# R9A09G057H register map
Vendor: Renesas Electronics; File version: 1.0
Registers are 32-bit, read-write, no defined reset value unless marked. A register's access mark holds for its fields unless they carry their own. Offsets are from the block's base; [hi:lo] are bit positions; {n}, {i} and the like mark numbered series; 'fields as' and 'values as' point back to an identical list.

## R_CPG — IO define file for cpg.
Base 0x10420010
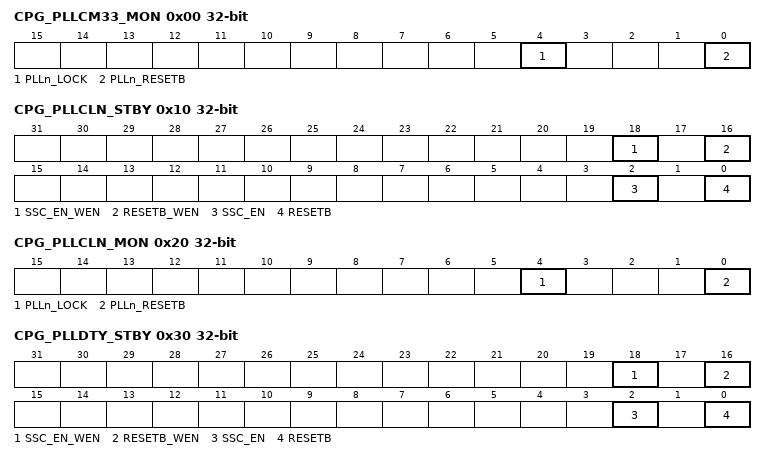
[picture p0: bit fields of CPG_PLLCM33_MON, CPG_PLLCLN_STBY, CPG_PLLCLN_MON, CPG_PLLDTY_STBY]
0x00 CPG_PLLCM33_MON ro
  [4] PLLn_LOCK, [0] PLLn_RESETB
0x10 CPG_PLLCLN_STBY
  [18] SSC_EN_WEN wo, [16] RESETB_WEN wo, [2] SSC_EN, [0] RESETB
0x20 CPG_PLLCLN_MON ro
  [4] PLLn_LOCK, [0] PLLn_RESETB
0x30 CPG_PLLDTY_STBY
  [18] SSC_EN_WEN wo, [16] RESETB_WEN wo, [2] SSC_EN, [0] RESETB
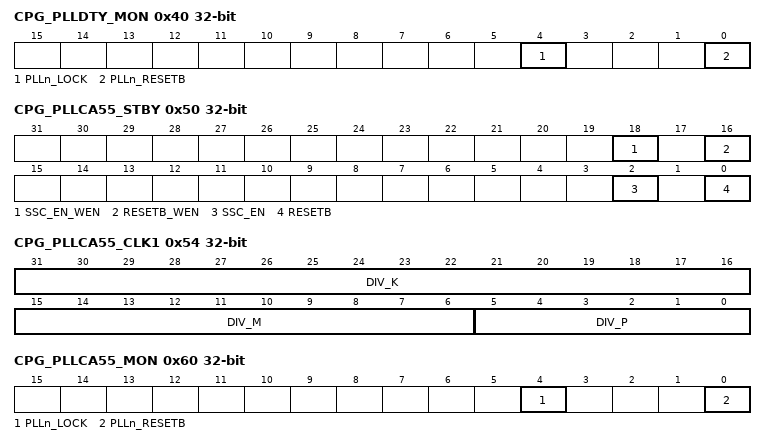
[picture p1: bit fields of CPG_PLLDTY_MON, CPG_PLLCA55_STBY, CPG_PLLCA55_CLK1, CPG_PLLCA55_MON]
0x40 CPG_PLLDTY_MON ro
  [4] PLLn_LOCK, [0] PLLn_RESETB
0x50 CPG_PLLCA55_STBY
  [18] SSC_EN_WEN wo, [16] RESETB_WEN wo, [2] SSC_EN, [0] RESETB
0x54 CPG_PLLCA55_CLK1
  [31:16] DIV_K, [15:6] DIV_M, [5:0] DIV_P
0x58 CPG_PLLCA55_CLK2
  [2:0] DIV_S
0x60 CPG_PLLCA55_MON ro
  [4] PLLn_LOCK, [0] PLLn_RESETB
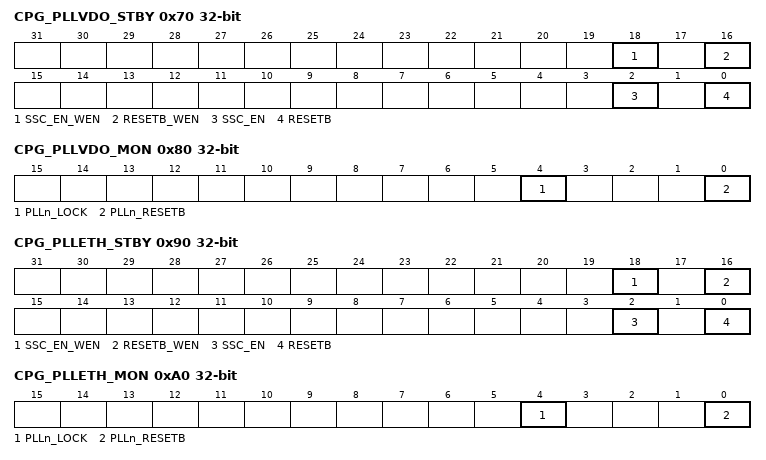
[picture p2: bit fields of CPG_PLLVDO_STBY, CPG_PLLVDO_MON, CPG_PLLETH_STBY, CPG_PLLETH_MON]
0x70 CPG_PLLVDO_STBY
  [18] SSC_EN_WEN wo, [16] RESETB_WEN wo, [2] SSC_EN, [0] RESETB
0x80 CPG_PLLVDO_MON ro
  [4] PLLn_LOCK, [0] PLLn_RESETB
0x90 CPG_PLLETH_STBY
  [18] SSC_EN_WEN wo, [16] RESETB_WEN wo, [2] SSC_EN, [0] RESETB
0xA0 CPG_PLLETH_MON ro
  [4] PLLn_LOCK, [0] PLLn_RESETB
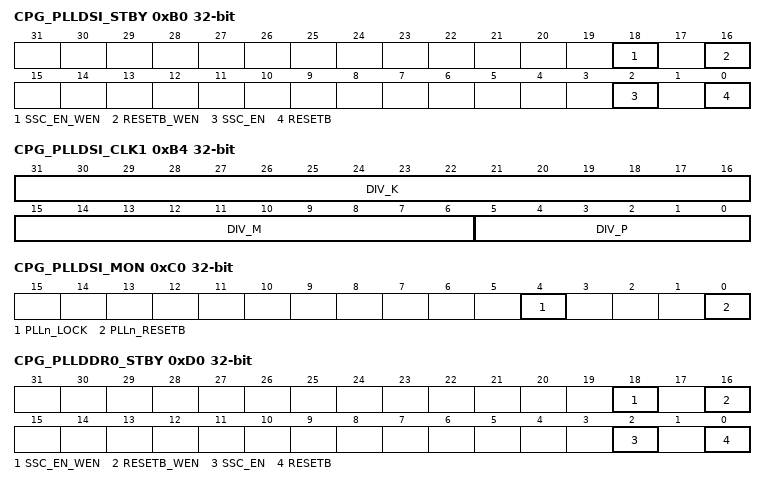
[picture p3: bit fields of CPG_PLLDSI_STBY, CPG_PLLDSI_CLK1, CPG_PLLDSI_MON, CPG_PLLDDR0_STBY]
0xB0 CPG_PLLDSI_STBY
  [18] SSC_EN_WEN wo, [16] RESETB_WEN wo, [2] SSC_EN, [0] RESETB
0xB4 CPG_PLLDSI_CLK1
  [31:16] DIV_K, [15:6] DIV_M, [5:0] DIV_P
0xB8 CPG_PLLDSI_CLK2
  [2:0] DIV_S
0xC0 CPG_PLLDSI_MON ro
  [4] PLLn_LOCK, [0] PLLn_RESETB
0xD0 CPG_PLLDDR0_STBY
  [18] SSC_EN_WEN wo, [16] RESETB_WEN wo, [2] SSC_EN, [0] RESETB
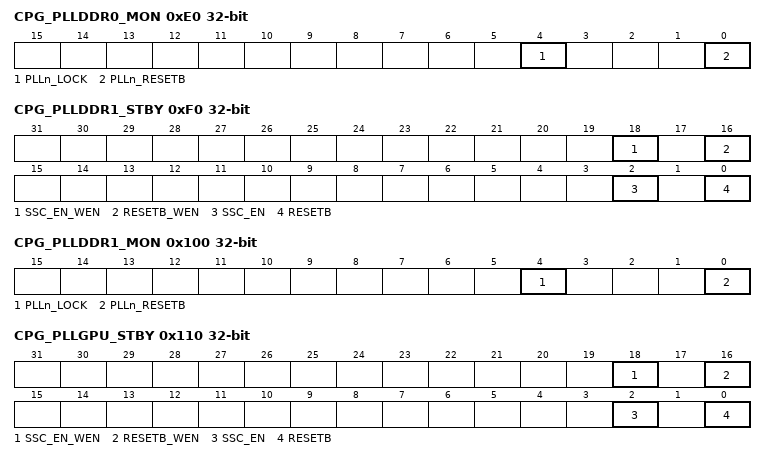
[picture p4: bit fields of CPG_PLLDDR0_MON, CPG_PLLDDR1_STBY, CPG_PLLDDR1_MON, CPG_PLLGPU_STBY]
0xE0 CPG_PLLDDR0_MON ro
  [4] PLLn_LOCK, [0] PLLn_RESETB
0xF0 CPG_PLLDDR1_STBY
  [18] SSC_EN_WEN wo, [16] RESETB_WEN wo, [2] SSC_EN, [0] RESETB
0x100 CPG_PLLDDR1_MON ro
  [4] PLLn_LOCK, [0] PLLn_RESETB
0x110 CPG_PLLGPU_STBY
  [18] SSC_EN_WEN wo, [16] RESETB_WEN wo, [2] SSC_EN, [0] RESETB
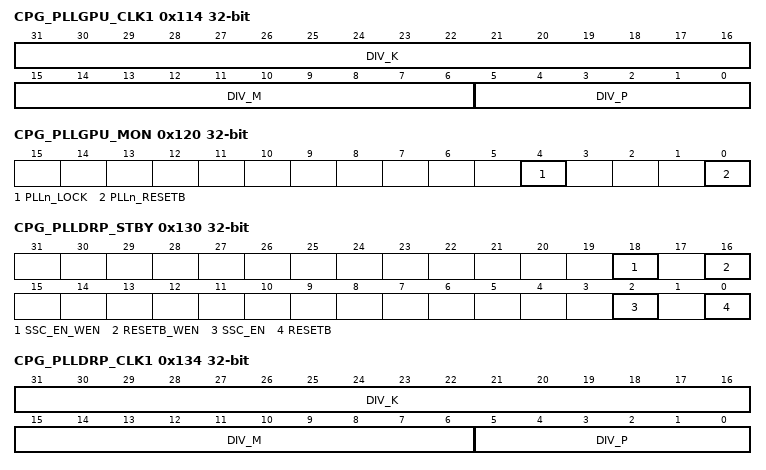
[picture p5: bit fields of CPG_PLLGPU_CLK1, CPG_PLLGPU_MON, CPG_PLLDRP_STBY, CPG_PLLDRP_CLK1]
0x114 CPG_PLLGPU_CLK1
  [31:16] DIV_K, [15:6] DIV_M, [5:0] DIV_P
0x118 CPG_PLLGPU_CLK2
  [2:0] DIV_S
0x120 CPG_PLLGPU_MON ro
  [4] PLLn_LOCK, [0] PLLn_RESETB
0x130 CPG_PLLDRP_STBY
  [18] SSC_EN_WEN wo, [16] RESETB_WEN wo, [2] SSC_EN, [0] RESETB
0x134 CPG_PLLDRP_CLK1
  [31:16] DIV_K, [15:6] DIV_M, [5:0] DIV_P
0x138 CPG_PLLDRP_CLK2
  [2:0] DIV_S
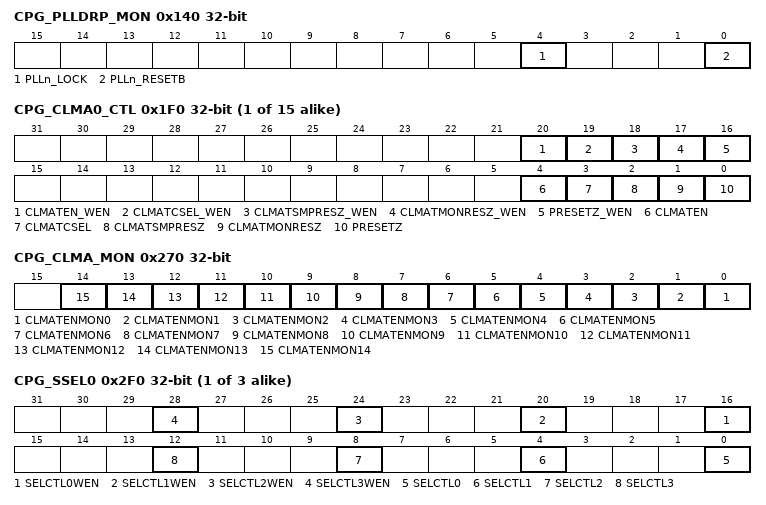
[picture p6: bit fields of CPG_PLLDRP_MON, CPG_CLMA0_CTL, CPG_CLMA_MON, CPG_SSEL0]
0x140 CPG_PLLDRP_MON ro
  [4] PLLn_LOCK, [0] PLLn_RESETB
{0x1F0+4i} CPG_CLMA{i}_CTL (i=0..14)
  [20] CLMATEN_WEN, [19] CLMATCSEL_WEN, [18] CLMATSMPRESZ_WEN, [17] CLMATMONRESZ_WEN, [16] PRESETZ_WEN, [4] CLMATEN, [3] CLMATCSEL, [2] CLMATSMPRESZ, [1] CLMATMONRESZ, [0] PRESETZ
0x270 CPG_CLMA_MON ro
  [n] CLMATENMON{n} (n=0..14)
{0x2F0+4i} CPG_SSEL{i} (i=0..2)
  [4n+16] SELCTL{n}WEN wo (n=0..3), [4n] SELCTL{n} (n=0..3)
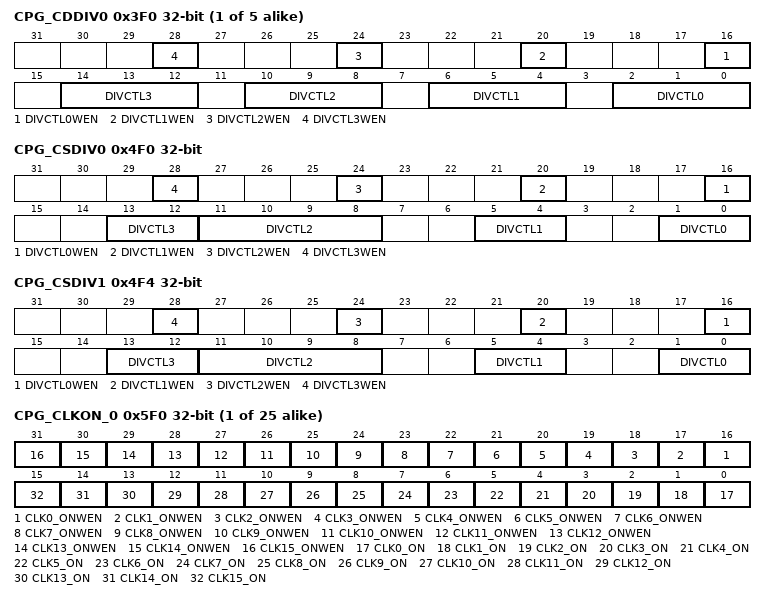
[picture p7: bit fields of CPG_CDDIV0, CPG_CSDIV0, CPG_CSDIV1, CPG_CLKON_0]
{0x3F0+4i} CPG_CDDIV{i} (i=0..4)
  [4n+16] DIVCTL{n}WEN wo (n=0..3), [4n+2:4n] DIVCTL{n} (n=0..3)
0x4F0 CPG_CSDIV0
  [4n+16] DIVCTL{n}WEN wo (n=0..3), [13:12] DIVCTL3, [11:8] DIVCTL2, [5:4] DIVCTL1, [1:0] DIVCTL0
0x4F4 CPG_CSDIV1
  fields as CPG_CSDIV0
{0x5F0+4i} CPG_CLKON_{i} (i=0..24)
  [n+16] CLK{n}_ONWEN wo (n=0..15), [n] CLK{n}_ON (n=0..15)
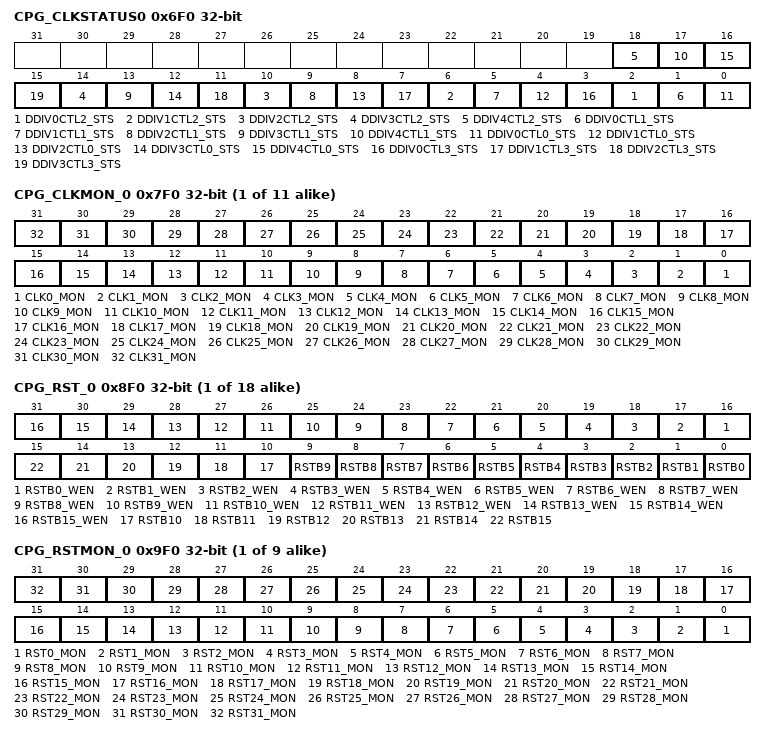
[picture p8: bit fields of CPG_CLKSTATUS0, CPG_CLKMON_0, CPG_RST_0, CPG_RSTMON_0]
0x6F0 CPG_CLKSTATUS0 ro
  [4n+2] DDIV{n}CTL2_STS (n=0..4), [4n+1] DDIV{n}CTL1_STS (n=0..4), [4n] DDIV{n}CTL0_STS (n=0..4), [4n+3] DDIV{n}CTL3_STS (n=0..3)
{0x7F0+4i} CPG_CLKMON_{i} ro (i=0..10)
  [n] CLK{n}_MON (n=0..31)
{0x8F0+4i} CPG_RST_{i} (i=0..17)
  [n+16] RSTB{n}_WEN wo (n=0..15), [n] RSTB{n} (n=0..15)
{0x9F0+4i} CPG_RSTMON_{i} ro (i=0..8)
  [n] RST{n}_MON (n=0..31)
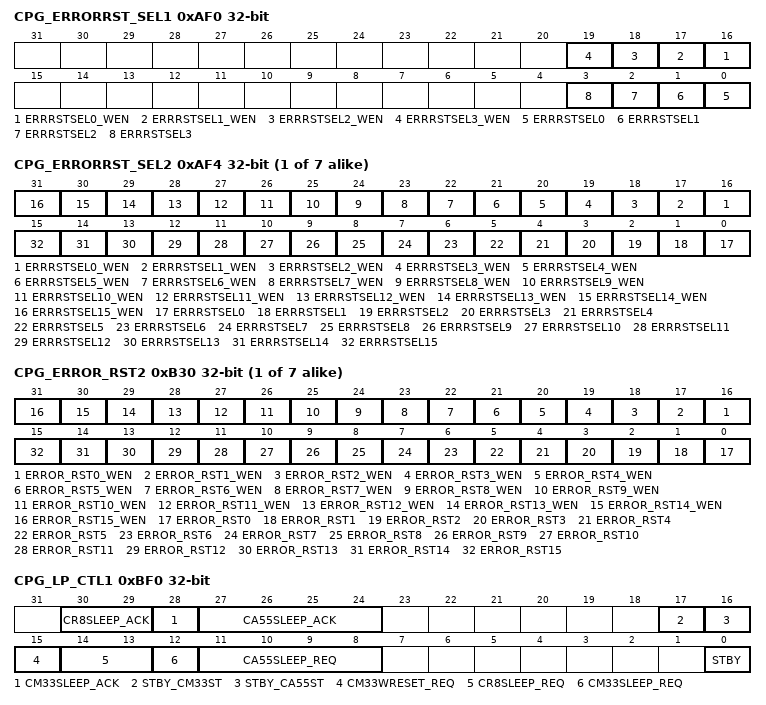
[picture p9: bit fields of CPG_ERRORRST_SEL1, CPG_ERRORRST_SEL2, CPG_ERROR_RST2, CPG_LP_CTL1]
0xAF0 CPG_ERRORRST_SEL1
  [n+16] ERRRSTSEL{n}_WEN wo (n=0..3), [n] ERRRSTSEL{n} (n=0..3)
{0xAEC+4i} CPG_ERRORRST_SEL{i} (i=2..8)
  [n+16] ERRRSTSEL{n}_WEN wo (n=0..15), [n] ERRRSTSEL{n} (n=0..15)
{0xB28+4i} CPG_ERROR_RST{i} (i=2..8)
  [n+16] ERROR_RST{n}_WEN wo (n=0..15), [n] ERROR_RST{n} (n=0..15)
0xBF0 CPG_LP_CTL1
  [30:29] CR8SLEEP_ACK, [28] CM33SLEEP_ACK, [27:24] CA55SLEEP_ACK, [17] STBY_CM33ST ro, [16] STBY_CA55ST ro, [15] CM33WRESET_REQ, [14:13] CR8SLEEP_REQ, [12] CM33SLEEP_REQ, [11:8] CA55SLEEP_REQ, [0] STBY
0xBF4 CPG_LP_CTL2
  [0] INTMASK_CM33_I
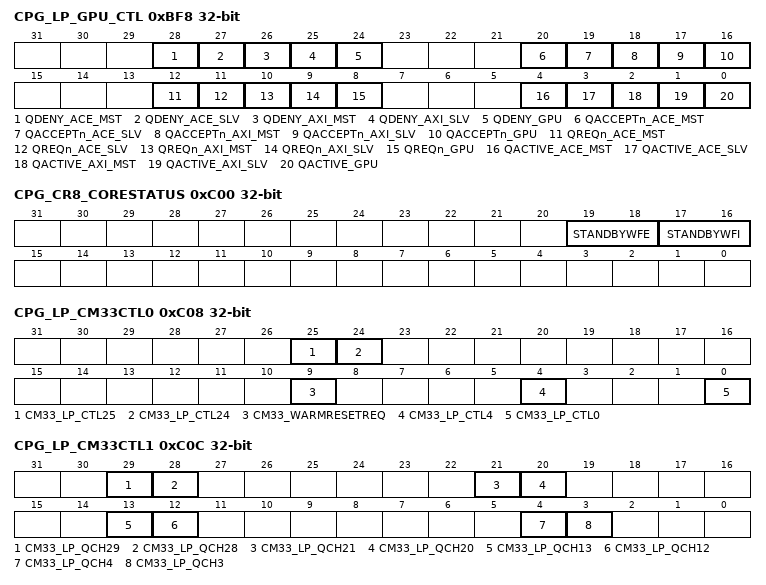
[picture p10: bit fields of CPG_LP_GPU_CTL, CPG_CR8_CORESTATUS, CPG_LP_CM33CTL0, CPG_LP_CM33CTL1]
0xBF8 CPG_LP_GPU_CTL
  [28] QDENY_ACE_MST ro, [27] QDENY_ACE_SLV ro, [26] QDENY_AXI_MST ro, [25] QDENY_AXI_SLV ro, [24] QDENY_GPU ro, [20] QACCEPTn_ACE_MST ro, [19] QACCEPTn_ACE_SLV ro, [18] QACCEPTn_AXI_MST ro, [17] QACCEPTn_AXI_SLV ro, [16] QACCEPTn_GPU ro, [12] QREQn_ACE_MST, [11] QREQn_ACE_SLV, [10] QREQn_AXI_MST, [9] QREQn_AXI_SLV, [8] QREQn_GPU, [4] QACTIVE_ACE_MST ro, [3] QACTIVE_ACE_SLV ro, [2] QACTIVE_AXI_MST ro, [1] QACTIVE_AXI_SLV ro, [0] QACTIVE_GPU ro
0xBFC CPG_CM33_CTL
  [0] CM33_BOOTCTL
0xC00 CPG_CR8_CORESTATUS ro
  [19:18] STANDBYWFE, [17:16] STANDBYWFI
0xC04 CPG_CR8_CONFIG1
  [1:0] nCPUHALT
0xC08 CPG_LP_CM33CTL0
  [25] CM33_LP_CTL25 ro, [24] CM33_LP_CTL24, [9] CM33_WARMRESETREQ ro, [4] CM33_LP_CTL4 ro, [0] CM33_LP_CTL0 ro
0xC0C CPG_LP_CM33CTL1
  [29] CM33_LP_QCH29 ro, [28] CM33_LP_QCH28 ro, [21] CM33_LP_QCH21 ro, [20] CM33_LP_QCH20 ro, [13] CM33_LP_QCH13, [12] CM33_LP_QCH12, [4] CM33_LP_QCH4 ro, [3] CM33_LP_QCH3 ro
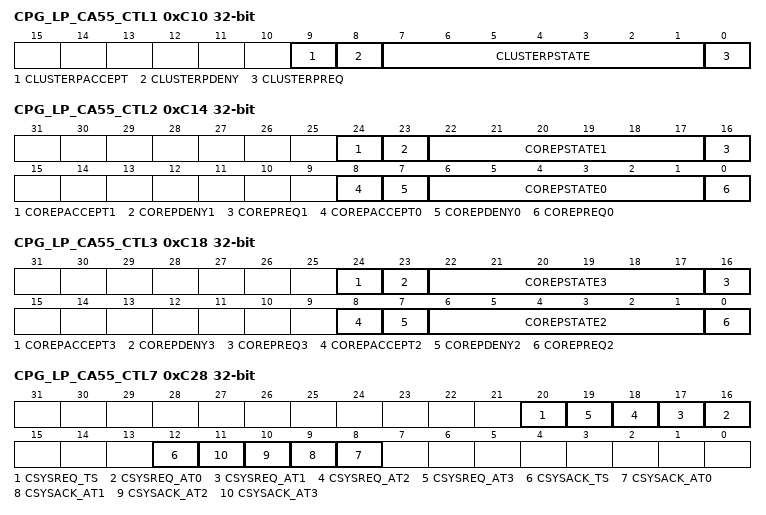
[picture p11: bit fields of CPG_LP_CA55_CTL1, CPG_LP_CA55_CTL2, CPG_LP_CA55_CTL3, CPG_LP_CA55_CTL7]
0xC10 CPG_LP_CA55_CTL1
  [9] CLUSTERPACCEPT ro, [8] CLUSTERPDENY ro, [7:1] CLUSTERPSTATE, [0] CLUSTERPREQ
0xC14 CPG_LP_CA55_CTL2
  [24] COREPACCEPT1 ro, [23] COREPDENY1 ro, [22:17] COREPSTATE1, [16] COREPREQ1, [8] COREPACCEPT0 ro, [7] COREPDENY0 ro, [6:1] COREPSTATE0, [0] COREPREQ0
0xC18 CPG_LP_CA55_CTL3
  [24] COREPACCEPT3 ro, [23] COREPDENY3 ro, [22:17] COREPSTATE3, [16] COREPREQ3, [8] COREPACCEPT2 ro, [7] COREPDENY2 ro, [6:1] COREPSTATE2, [0] COREPREQ2
0xC24 CPG_LP_CA55_CTL6 ro
  [3:0] COREINSTRRUN
0xC28 CPG_LP_CA55_CTL7
  [20] CSYSREQ_TS, [n+16] CSYSREQ_AT{n} (n=0..3), [12] CSYSACK_TS ro, [n+8] CSYSACK_AT{n} ro (n=0..3)
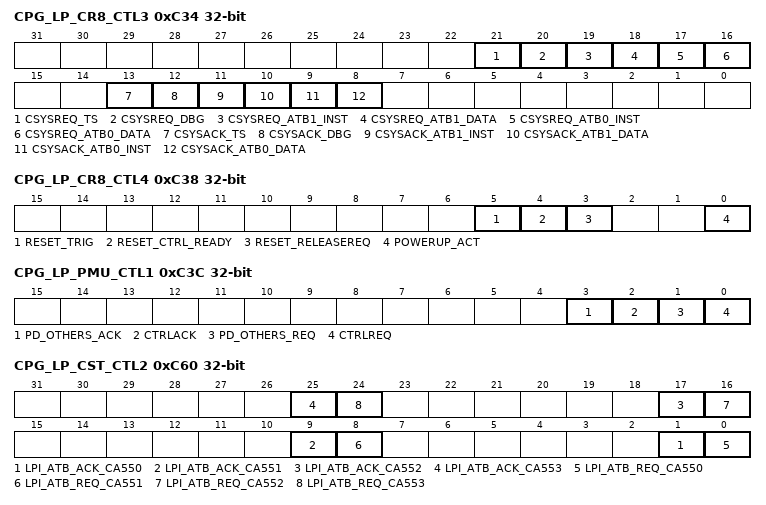
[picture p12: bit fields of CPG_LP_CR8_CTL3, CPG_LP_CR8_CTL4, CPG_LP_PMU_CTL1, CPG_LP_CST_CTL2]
0xC34 CPG_LP_CR8_CTL3
  [21] CSYSREQ_TS, [20] CSYSREQ_DBG, [19] CSYSREQ_ATB1_INST, [18] CSYSREQ_ATB1_DATA, [17] CSYSREQ_ATB0_INST, [16] CSYSREQ_ATB0_DATA, [13] CSYSACK_TS ro, [12] CSYSACK_DBG ro, [11] CSYSACK_ATB1_INST ro, [10] CSYSACK_ATB1_DATA ro, [9] CSYSACK_ATB0_INST ro, [8] CSYSACK_ATB0_DATA ro
0xC38 CPG_LP_CR8_CTL4
  [5] RESET_TRIG, [4] RESET_CTRL_READY ro, [3] RESET_RELEASEREQ ro, [0] POWERUP_ACT ro
0xC3C CPG_LP_PMU_CTL1
  [3] PD_OTHERS_ACK ro, [2] CTRLACK ro, [1] PD_OTHERS_REQ, [0] CTRLREQ
{0xC3C+4i} CPG_LP_SRAM_STBY_CTL{i} ro (i=1..3)
  [31:0] SRAM_STBY_CTL
0xC60 CPG_LP_CST_CTL2
  [8n-4399] LPI_ATB_ACK_CA{n} ro (n=550..553), [8n-4400] LPI_ATB_REQ_CA{n} (n=550..553)
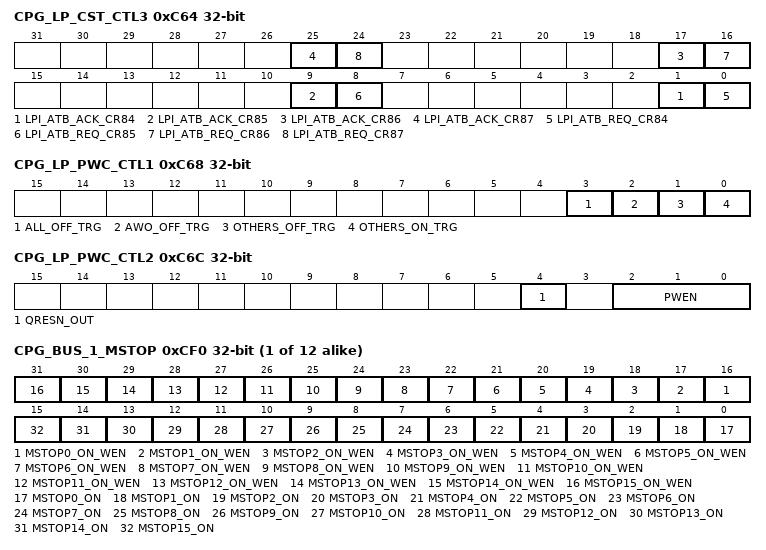
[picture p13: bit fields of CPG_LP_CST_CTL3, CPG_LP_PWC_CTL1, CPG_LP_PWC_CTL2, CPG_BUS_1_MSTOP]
0xC64 CPG_LP_CST_CTL3
  [8n-671] LPI_ATB_ACK_CR{n} ro (n=84..87), [8n-672] LPI_ATB_REQ_CR{n} (n=84..87)
0xC68 CPG_LP_PWC_CTL1
  [3] ALL_OFF_TRG, [2] AWO_OFF_TRG, [1] OTHERS_OFF_TRG, [0] OTHERS_ON_TRG
0xC6C CPG_LP_PWC_CTL2 ro
  [4] QRESN_OUT, [2:0] PWEN
0xC78 CPG_OTP_HANDSHAKE_MON ro
  [0] DFT_DONE
0xC7C CPG_OTHERS_INI
  [0] OTHERS_RST
{0xCEC+4i} CPG_BUS_{i}_MSTOP (i=1..12)
  [n+16] MSTOP{n}_ON_WEN wo (n=0..15), [n] MSTOP{n}_ON (n=0..15)
